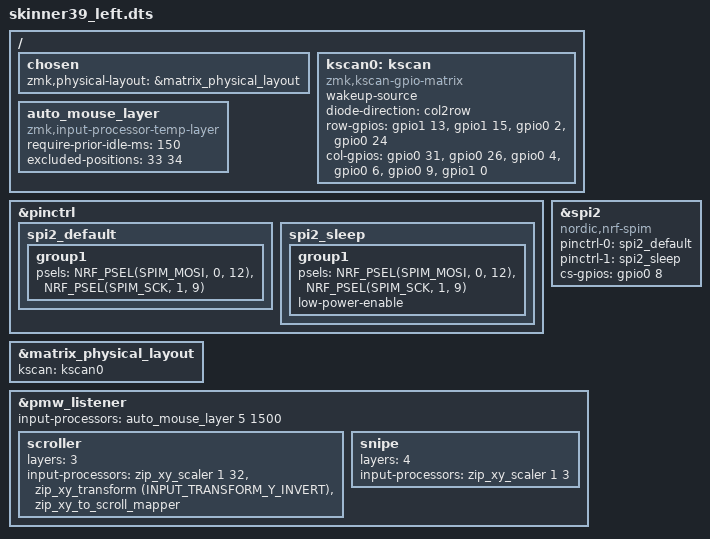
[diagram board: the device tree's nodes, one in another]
#include "skinner39.dtsi"
#include <dt-bindings/led/led.h>
#include <input/processors.dtsi>
#include <dt-bindings/zmk/input_transform.h>
#include <zephyr/dt-bindings/input/input-event-codes.h>


&pinctrl {
    spi2_default: spi2_default {
				group1 {
						psels = <NRF_PSEL(SPIM_MOSI, 0, 12)>,
						<NRF_PSEL(SPIM_SCK, 1, 9)>;
				};
		};
	
    spi2_sleep: spi2_sleep {
				group1 {
						psels = <NRF_PSEL(SPIM_MOSI, 0, 12)>,
						<NRF_PSEL(SPIM_SCK, 1, 9)>;
						low-power-enable;
				};
		};
};


lpm_view_spi: &spi2 {
    compatible = "nordic,nrf-spim";
    pinctrl-0 = <&spi2_default>;
    pinctrl-1 = <&spi2_sleep>;
    pinctrl-names = "default", "sleep";
    cs-gpios = <&gpio0 8 (GPIO_ACTIVE_HIGH | GPIO_PULL_DOWN) >;
};

nice_view_spi: &spi2 {
    compatible = "nordic,nrf-spim";
    pinctrl-0 = <&spi2_default>;
    pinctrl-1 = <&spi2_sleep>;
    pinctrl-names = "default", "sleep";
    cs-gpios = <&gpio0 8 (GPIO_ACTIVE_HIGH | GPIO_PULL_DOWN) >;
};



&matrix_physical_layout {
  	kscan = <&kscan0>;
};

/ {
	chosen {
		zmk,physical-layout = &matrix_physical_layout;
	};
    kscan0: kscan {
        compatible = "zmk,kscan-gpio-matrix";
        wakeup-source;

        diode-direction = "col2row";
        row-gpios
            = <&gpio1 13 (GPIO_ACTIVE_HIGH | GPIO_PULL_DOWN)>
            , <&gpio1 15 (GPIO_ACTIVE_HIGH | GPIO_PULL_DOWN)>
            , <&gpio0 2 (GPIO_ACTIVE_HIGH | GPIO_PULL_DOWN)>
            , <&gpio0 24 (GPIO_ACTIVE_HIGH | GPIO_PULL_DOWN)>
            ;

			col-gpios
							= <&gpio0 31 (GPIO_ACTIVE_HIGH | GPIO_PULL_DOWN)>
							, <&gpio0 26 (GPIO_ACTIVE_HIGH | GPIO_PULL_DOWN)>
							, <&gpio0 4 (GPIO_ACTIVE_HIGH | GPIO_PULL_DOWN)>
							, <&gpio0 6 (GPIO_ACTIVE_HIGH | GPIO_PULL_DOWN)>
							, <&gpio0 9 (GPIO_ACTIVE_HIGH | GPIO_PULL_DOWN)>
							, <&gpio1 0 (GPIO_ACTIVE_HIGH | GPIO_PULL_DOWN)>;
    };
};

/ {
	auto_mouse_layer: auto_mouse_layer {
		compatible = "zmk,input-processor-temp-layer";
		#input-processor-cells = <2>;
		require-prior-idle-ms = <150>;
		excluded-positions = <33 34>;  // Mouse button positions - clicking them keeps layer active and resets timeout
	};
};

&pmw_listener {
	status = "okay";

	// Default behavior: auto-activate mouse layer when trackball moves
	// Layer 5 is activated for 1500ms and exits on any non-mouse keypress
	// Mouse button clicks (positions 33, 34) reset the timeout to keep layer active
	input-processors = <&auto_mouse_layer 5 1500>;

	// when layer 3 is active, the trackball will act as a mouse wheel
	scroller {
		layers = <3>;
		input-processors = <&zip_xy_scaler 1 32>, <&zip_xy_transform (INPUT_TRANSFORM_Y_INVERT)>, <&zip_xy_to_scroll_mapper>;
	};
	// default when layer 4 is active, the trackball will move more slowly
		snipe {
		layers = <4>;
		input-processors = <&zip_xy_scaler 1 3>;
	};
};
